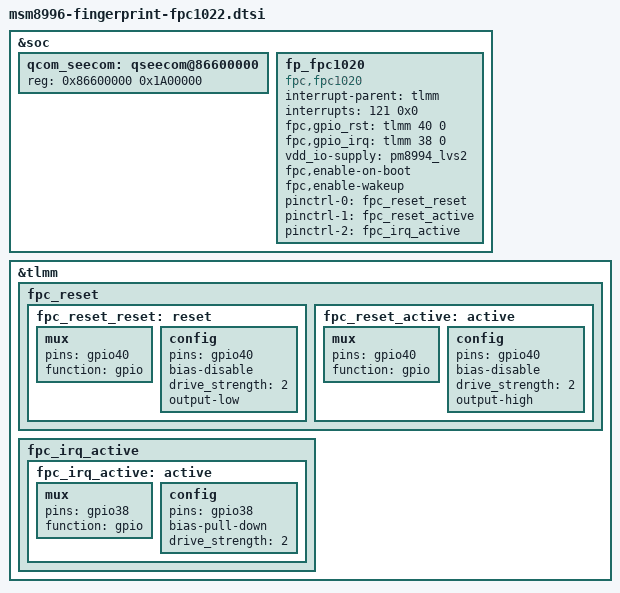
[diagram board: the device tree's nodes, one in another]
/* Copyright (c) 2017, The Linux Foundation. All rights reserved.
 *
 * This program is free software; you can redistribute it and/or modify
 * it under the terms of the GNU General Public License version 2 and
 * only version 2 as published by the Free Software Foundation.
 *
 * This program is distributed in the hope that it will be useful,
 * but WITHOUT ANY WARRANTY; without even the implied warranty of
 * MERCHANTABILITY or FITNESS FOR A PARTICULAR PURPOSE.  See the
 * GNU General Public License for more details.
 */

&soc {
	qcom_seecom: qseecom@86600000 {
		reg = <0x86600000 0x1A00000>;
	};

	fp_fpc1020 {
		status = "ok";
		compatible = "fpc,fpc1020";
		interrupt-parent = <&tlmm>;
		interrupts = <121 0x0>;
		fpc,gpio_rst	= <&tlmm 40 0>;
		fpc,gpio_irq	= <&tlmm 38 0>;
		/* vcc_spi-supply  = <&pm8994_s4>; */
		vdd_io-supply	= <&pm8994_lvs2>; /*default regulator to lvs2 since rev.c*/
		/* vdd_ana-supply  = <&pm8996_l18>; */
		fpc,enable-on-boot;
		fpc,enable-wakeup;

		pinctrl-names = "fpc1020_reset_reset",
			"fpc1020_reset_active",
			"fpc1020_irq_active";

		pinctrl-0 = <&fpc_reset_reset>;
		pinctrl-1 = <&fpc_reset_active>;
		pinctrl-2 = <&fpc_irq_active>;
	};
};

&tlmm {
		fpc_reset {
			fpc_reset_reset: reset {
				mux {
					pins = "gpio40";
					function = "gpio";
				};

				config {
					pins = "gpio40";
					bias-disable;
					drive_strength = <2>;
					output-low;
				};
			};
			fpc_reset_active: active {
				mux {
					pins = "gpio40";
					function = "gpio";
				};

				config {
					pins = "gpio40";
					bias-disable;
					drive_strength = <2>;
					output-high;
				};
			};
		};

		fpc_irq_active {
			fpc_irq_active: active {
				mux {
					pins = "gpio38";
					function = "gpio";
				};

				config {
					pins = "gpio38";
					bias-pull-down;
					drive_strength = <2>;
				};
			};
		};

};
